# C2000_CLA_CRC32_Registers register map
Vendor: Texas Instruments
Peripheral module from a debugger description file (folder C2000).
Address unit: 16 bits
Registers are 32-bit, access not given, reset 0x0 unless marked. A register's access mark holds for its fields unless they carry their own. Offsets are as the file gives them; lines under a group give offsets from that group; [hi:lo] are bit positions; {n}, {i} and the like mark numbered series; 'fields as' and 'values as' point back to an identical list; <NAME> marks a mode.

## CLA_PROM_CRC32 — CLA PROM CRC32 Registers
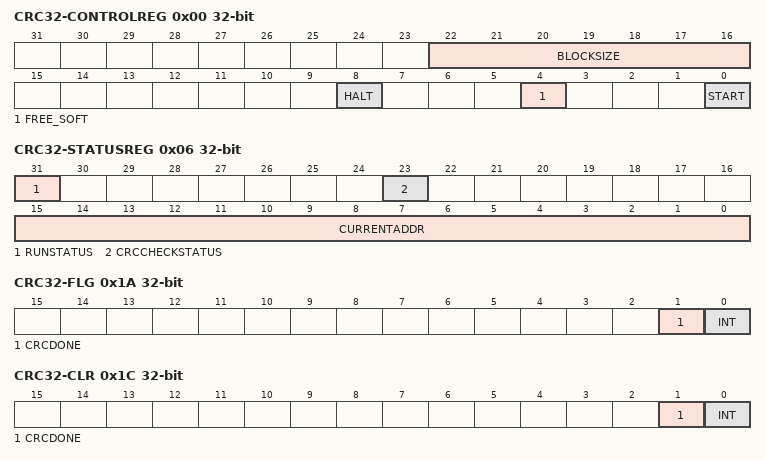
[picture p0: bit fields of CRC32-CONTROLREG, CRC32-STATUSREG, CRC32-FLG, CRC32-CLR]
0x00 CRC32-CONTROLREG rw — CRC32-Control Register
  [22:16] BLOCKSIZE — Block size of ROM for which CRC is to be calculated
  [8] HALT — Halt Bit
  [4] FREE_SOFT — Emulation Control Bit
  [0] START — Start Bit
0x02 CRC32-STARTADDRESS reset not defined
0x04 CRC32-SEED reset not defined
0x06 CRC32-STATUSREG ro — CRC32-Status Register
  [31] RUNSTATUS — CRC active status
  [23] CRCCHECKSTATUS — CRC active status
  [15:0] CURRENTADDR — Point to the data fetch unit current address
0x08 CRC32-CRCRESULT reset not defined
0x0A CRC32-GOLDENCRC reset not defined
0x18 CRC32-INTEN rw — CRC32-Interrupt Enable Register
  [1] CRCDONE — CRCDONE interrupt enable register
0x1A CRC32-FLG ro — CRC32-Interrupt Flag Register
  [1] CRCDONE — CRCDONE interrupt status flag
  [0] INT — Global Interrupt Status Flag
0x1C CRC32-CLR rw — CRC32-Interrupt Clear Register
  [1] CRCDONE — CRCDONE interrupt clear
  [0] INT — Global Interrupt clear
0x1E CRC32-FRC wo — CRC32-Interrupt Force Register
  [1] CRCDONE — CRCDONE interrupt force
